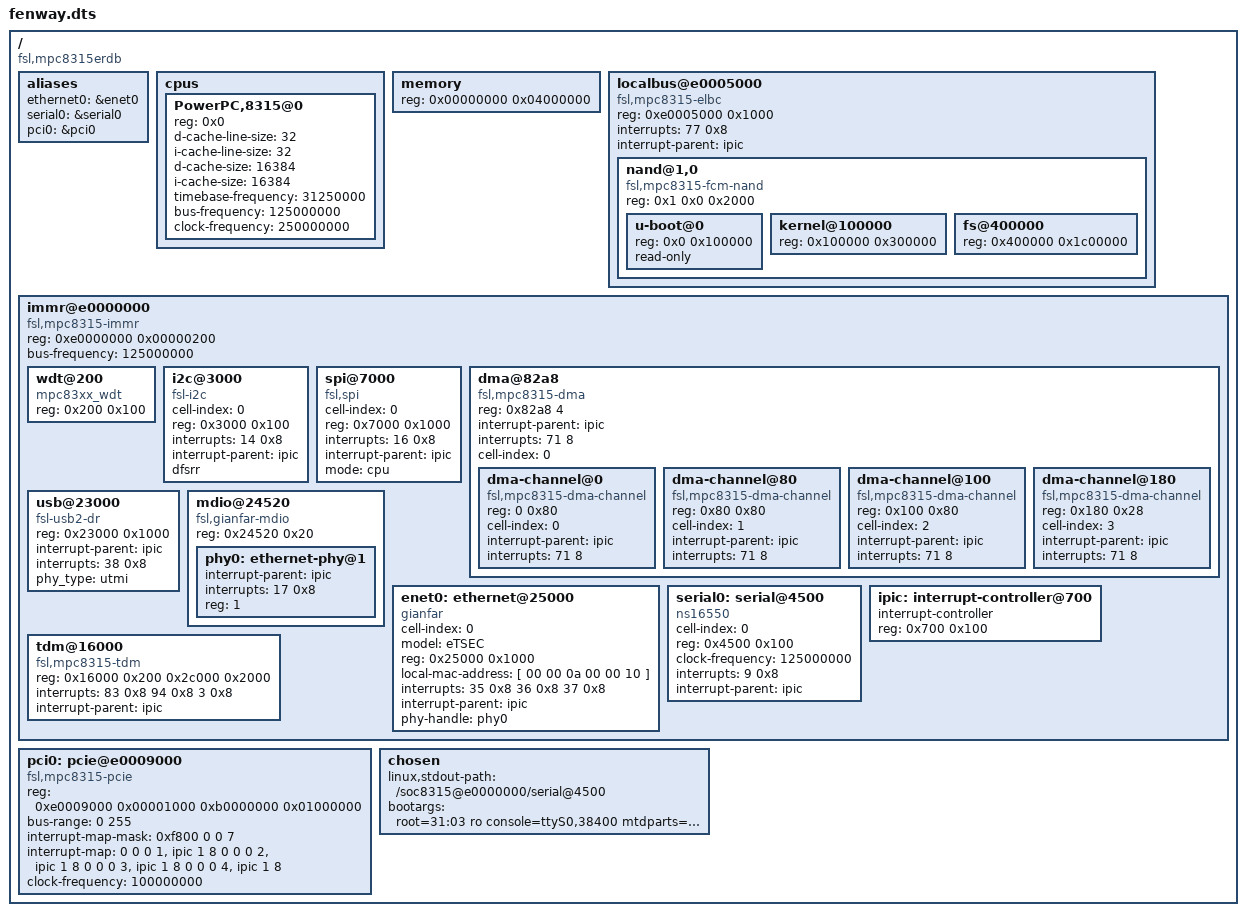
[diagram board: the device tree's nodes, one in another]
/*
 * Fenway Device Tree Source
 * NOTE: This is for Proto 2 (and later) ONLY
 * Assumes 64M of RAM and PHY management address 0x01
 *
 * Copyright 2007 Freescale Semiconductor Inc.
 *
 * This program is free software; you can redistribute  it and/or modify it
 * under  the terms of  the GNU General  Public License as published by the
 * Free Software Foundation;  either version 2 of the  License, or (at your
 * option) any later version.
 */

/dts-v1/;

/ {
	compatible = "fsl,mpc8315erdb";
	#address-cells = <1>;
	#size-cells = <1>;

	aliases {
		ethernet0 = &enet0;
		serial0 = &serial0;
		pci0 = &pci0;
	};

	cpus {
		#address-cells = <1>;
		#size-cells = <0>;

		PowerPC,8315@0 {
			device_type = "cpu";
			reg = <0x0>;
			d-cache-line-size = <32>;
			i-cache-line-size = <32>;
			d-cache-size = <16384>;
			i-cache-size = <16384>;
			timebase-frequency = <31250000>;   // from bootloader
			bus-frequency =      <125000000>;  // from bootloader
			clock-frequency =    <250000000>;  // from bootloader
		};
	};

	memory {
		device_type = "memory";
		reg = <0x00000000 0x04000000>;	// 64MB at 0
	};

	localbus@e0005000 {
		#address-cells = <2>;
		#size-cells = <1>;
		compatible = "fsl,mpc8315-elbc", "fsl,elbc", "simple-bus";
		reg = <0xe0005000 0x1000>;
		interrupts = <77 0x8>;
		interrupt-parent = <&ipic>;

		// CS0 and CS1 are swapped when
		// booting from nand, but the
		// addresses are the same.
		ranges = <0x0 0x0 0xfe000000 0x00800000
		          0x1 0x0 0xe0600000 0x00002000
		          0x2 0x0 0xf0000000 0x00020000
		          0x3 0x0 0xfa000000 0x00008000>;

		nand@1,0 {
			#address-cells = <1>;
			#size-cells = <1>;
			compatible = "fsl,mpc8315-fcm-nand",
			             "fsl,elbc-fcm-nand";
			reg = <0x1 0x0 0x2000>;

			u-boot@0 {
				reg = <0x0 0x100000>;
				read-only;
			};

			kernel@100000 {
				reg = <0x100000 0x300000>;
			};
			fs@400000 {
				reg = <0x400000 0x1c00000>;
			};
		};
	};

	immr@e0000000 {
		#address-cells = <1>;
		#size-cells = <1>;
		device_type = "soc";
		compatible = "fsl,mpc8315-immr", "simple-bus";
		ranges = <0 0xe0000000 0x00100000>;
		reg = <0xe0000000 0x00000200>;
		bus-frequency = <125000000>;

		wdt@200 {
			device_type = "watchdog";
			compatible = "mpc83xx_wdt";
			reg = <0x200 0x100>;
		};

		i2c@3000 {
			#address-cells = <1>;
			#size-cells = <0>;
			cell-index = <0>;
			compatible = "fsl-i2c";
			reg = <0x3000 0x100>;
			interrupts = <14 0x8>;
			interrupt-parent = <&ipic>;
			dfsrr;
		};

		spi@7000 {
			cell-index = <0>;
			compatible = "fsl,spi";
			reg = <0x7000 0x1000>;
			interrupts = <16 0x8>;
			interrupt-parent = <&ipic>;
			mode = "cpu";
		};

		dma@82a8 {
			#address-cells = <1>;
			#size-cells = <1>;
			compatible = "fsl,mpc8315-dma", "fsl,elo-dma";
			reg = <0x82a8 4>;
			ranges = <0 0x8100 0x1a8>;
			interrupt-parent = <&ipic>;
			interrupts = <71 8>;
			cell-index = <0>;
			dma-channel@0 {
				compatible = "fsl,mpc8315-dma-channel", "fsl,elo-dma-channel";
				reg = <0 0x80>;
				cell-index = <0>;
				interrupt-parent = <&ipic>;
				interrupts = <71 8>;
			};
			dma-channel@80 {
				compatible = "fsl,mpc8315-dma-channel", "fsl,elo-dma-channel";
				reg = <0x80 0x80>;
				cell-index = <1>;
				interrupt-parent = <&ipic>;
				interrupts = <71 8>;
			};
			dma-channel@100 {
				compatible = "fsl,mpc8315-dma-channel", "fsl,elo-dma-channel";
				reg = <0x100 0x80>;
				cell-index = <2>;
				interrupt-parent = <&ipic>;
				interrupts = <71 8>;
			};
			dma-channel@180 {
				compatible = "fsl,mpc8315-dma-channel", "fsl,elo-dma-channel";
				reg = <0x180 0x28>;
				cell-index = <3>;
				interrupt-parent = <&ipic>;
				interrupts = <71 8>;
			};
		};

		usb@23000 {
			compatible = "fsl-usb2-dr";
			reg = <0x23000 0x1000>;
			#address-cells = <1>;
			#size-cells = <0>;
			interrupt-parent = <&ipic>;
			interrupts = <38 0x8>;
			phy_type = "utmi";
		};

		mdio@24520 {
			#address-cells = <1>;
			#size-cells = <0>;
			compatible = "fsl,gianfar-mdio";
			reg = <0x24520 0x20>;
			phy0: ethernet-phy@1 {
				interrupt-parent = <&ipic>;
				interrupts = <17 0x8>;
				reg = <1>;
				device_type = "ethernet-phy";
			};
		};


		enet0: ethernet@25000 {
			cell-index = <0>;
			device_type = "network";
			model = "eTSEC";
			compatible = "gianfar";
			reg = <0x25000 0x1000>;
			local-mac-address = [ 00 00 0a 00 00 10 ];
			interrupts = <35 0x8 36 0x8 37 0x8>;
			interrupt-parent = <&ipic>;
			phy-handle = < &phy0 >;
		};

		serial0: serial@4500 {
			cell-index = <0>;
			device_type = "serial";
			compatible = "ns16550";
			reg = <0x4500 0x100>;
			clock-frequency = <125000000>;
			interrupts = <9 0x8>;
			interrupt-parent = <&ipic>;
		};

		/* IPIC
		 * interrupts cell = <intr #, sense>
		 * sense values match linux IORESOURCE_IRQ_* defines:
		 * sense == 8: Level, low assertion
		 * sense == 2: Edge, high-to-low change
		 */
		ipic: interrupt-controller@700 {
			interrupt-controller;
			#address-cells = <0>;
			#interrupt-cells = <2>;
			reg = <0x700 0x100>;
			device_type = "ipic";
		};

		tdm@16000 {
			compatible = "fsl,mpc8315-tdm";
			reg = <0x16000 0x200 0x2c000 0x2000>;
			interrupts = <83 0x8 94 0x8 3 0x8>;
			interrupt-parent = <&ipic>;
		};

	};

	pci0: pcie@e0009000 {
		#address-cells = <3>;
		#size-cells = <2>;
		#interrupt-cells = <1>;
		device_type = "pci";
		compatible = "fsl,mpc8315-pcie", "fsl,mpc8314-pcie";
		reg = <0xe0009000 0x00001000
                       0xb0000000 0x01000000>;
		ranges = <0x02000000 0 0xa0000000 0xa0000000 0 0x10000000
		          0x01000000 0 0x00000000 0xb1000000 0 0x00800000>;
		bus-range = <0 255>;
		interrupt-map-mask = <0xf800 0 0 7>;
		interrupt-map = <0 0 0 1 &ipic 1 8
				 0 0 0 2 &ipic 1 8
				 0 0 0 3 &ipic 1 8
				 0 0 0 4 &ipic 1 8>;
		clock-frequency = <100000000>;
	};

	chosen {
		linux,stdout-path = "/soc8315@e0000000/serial@4500";
		bootargs = "root=31:03 ro console=ttyS0,38400 mtdparts=e0600000.flash:1024k(u-boot),7168k(jffs2),5120k(Ramdisk),16384k(rootfs),2048k(kernel),1024k(obsolete-dtb)";
	};
};
